AUTOSAR XML (schema 00053)
package /Services
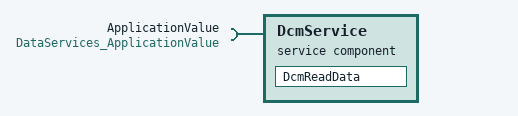
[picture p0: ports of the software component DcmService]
  service sw component type DcmService
    require port ApplicationValue: client-com-spec=ReadData, required-interface=DataServices_ApplicationValue
    behavior Behavior
      runnable DcmReadData: symbol=DcmService_ReadData
        sync call ReadApplicationValue: operation=ApplicationValue.ReadData
